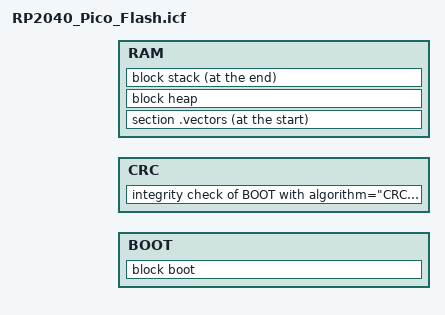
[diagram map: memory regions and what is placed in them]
/*********************************************************************
*                    SEGGER Microcontroller GmbH                     *
*                        The Embedded Experts                        *
**********************************************************************
*                                                                    *
*            (c) 2014 - 2021 SEGGER Microcontroller GmbH             *
*                                                                    *
*       www.segger.com     Support: support@segger.com               *
*                                                                    *
**********************************************************************
*                                                                    *
* All rights reserved.                                               *
*                                                                    *
* Redistribution and use in source and binary forms, with or         *
* without modification, are permitted provided that the following    *
* condition is met:                                                  *
*                                                                    *
* - Redistributions of source code must retain the above copyright   *
*   notice, this condition and the following disclaimer.             *
*                                                                    *
* THIS SOFTWARE IS PROVIDED BY THE COPYRIGHT HOLDERS AND             *
* CONTRIBUTORS "AS IS" AND ANY EXPRESS OR IMPLIED WARRANTIES,        *
* INCLUDING, BUT NOT LIMITED TO, THE IMPLIED WARRANTIES OF           *
* MERCHANTABILITY AND FITNESS FOR A PARTICULAR PURPOSE ARE           *
* DISCLAIMED. IN NO EVENT SHALL SEGGER Microcontroller BE LIABLE FOR *
* ANY DIRECT, INDIRECT, INCIDENTAL, SPECIAL, EXEMPLARY, OR           *
* CONSEQUENTIAL DAMAGES (INCLUDING, BUT NOT LIMITED TO, PROCUREMENT  *
* OF SUBSTITUTE GOODS OR SERVICES; LOSS OF USE, DATA, OR PROFITS;    *
* OR BUSINESS INTERRUPTION) HOWEVER CAUSED AND ON ANY THEORY OF      *
* LIABILITY, WHETHER IN CONTRACT, STRICT LIABILITY, OR TORT          *
* (INCLUDING NEGLIGENCE OR OTHERWISE) ARISING IN ANY WAY OUT OF THE  *
* USE OF THIS SOFTWARE, EVEN IF ADVISED OF THE POSSIBILITY OF SUCH   *
* DAMAGE.                                                            *
*                                                                    *
**********************************************************************
-------------------------- END-OF-HEADER -----------------------------

File    : RP2040_Pico_Flash.icf
Purpose : Linker script for RP2040 Pico board,
          for use with the SEGGER Linker.
Literature:
  [1]  SEGGER Linker User Guide (https://www.segger.com/doc/UM20005_Linker.html)
  [2]  SEGGER Linker Section Placement (https://wiki.segger.com/SEGGER_Linker_Script_Files)
*/

define memory with size = 4G;

//
// Combined regions per memory type
//
define region BOOT  = [from 0x20041F00 to 0x20041FFB];  // Copied  by ROM BTL of RP2040 to the end of the internal RAM
define region CRC   = [from 0x20041FFC to 0x20041FFF];  // Checked by ROM BTL of RP2040 to determine if 2nd stage BTL is valid and can be booted
define region FLASH = [from 0x10000000 to 0x10FFFFFF];
define region RAM   = [from 0x20000000 to 0x2003FFFF];
//
// Block definitions
//
define block boot                           { symbol _Stage2BTL };  // RP2040 2nd stage BTL section
define block ctors                          { section .ctors,     section .ctors.*, block with         alphabetical order { init_array } };
define block dtors                          { section .dtors,     section .dtors.*, block with reverse alphabetical order { fini_array } };
define block exidx                          { section .ARM.exidx, section .ARM.exidx.* };
define block tbss                           { section .tbss,      section .tbss.*  };
define block tdata                          { section .tdata,     section .tdata.* };
define block tls                            { block tbss, block tdata };
define block tdata_load                     { copy of block tdata };
define block heap  with size = __HEAPSIZE__,  alignment = 8, /* fill =0x00, */ readwrite access { };
define block stack with size = __STACKSIZE__, alignment = 8, /* fill =0xCD, */ readwrite access { };
//
// Explicit initialization settings for sections
// Packing options for initialize by copy: packing=auto/lzss/zpak/packbits
//
do not initialize                           { section .non_init, section .non_init.*, section .*.non_init, section .*.non_init.* };
do not initialize                           { section .no_init, section .no_init.*, section .*.no_init, section .*.no_init.* };   // Legacy sections, kept for backwards compatibility
do not initialize                           { section .noinit, section .noinit.*, section .*.noinit, section .*.noinit.* };       // Legacy sections, used by some SDKs/HALs
do not initialize                           { section .vectors_ram };
initialize by copy with packing=auto        { section .data, section .data.*, section .*.data, section .*.data.* };               // Static data sections
initialize by copy with packing=auto        { section .fast, section .fast.* };                                                   // "RAM Code" sections
initialize by symbol __SEGGER_init_heap     { block heap  };                                        // Init the heap if there is one
initialize by symbol __SEGGER_init_ctors    { block ctors };                                        // Call constructors for global objects which need to be constructed before reaching main (if any). Make sure this is done after setting up heap.
//
// FLASH Placement
//
// Special: Fill BOOT region (2nd stage BTL) with 0xFF to make sure that resulting hex file does not contain any gaps there.
// This is needed to actually force ES to perform 0xFF writes for this region when passing the download data to J-Link.
// Otherwise, it could happen that J-Link SW version V7.64c and earlier merge the gap with read data from the target.
// Merging with read data from the target is problematic if the 2nd stage BTL was bigger before and now is smaller,
// so that something that is a gap in the new BTL was != 0xFF in the old one.
// Here, reading back data from the target and merging it into the download data would mess up the CRC we calculated in the linker.
//
fill BOOT with 0xFF;
place in BOOT                               { block boot };                                         // RP2040 2nd stage BTL
place in CRC                                { integrity check of BOOT with algorithm="CRC-32/STM32" fill=0xFF }; // Placement of CRC
//
// RAM Placement
//
place at start of RAM                       { section .vectors };                                   // Vector table section
place in RAM with minimum size order        { block tdata_load,                                     // Thread-local-storage load image
                                              block exidx,                                          // ARM exception unwinding block
                                              block ctors,                                          // Constructors block
                                              block dtors,                                          // Destructors block
                                              readonly,                                             // Catch-all for readonly data (e.g. .rodata, .srodata)
                                              readexec                                              // Catch-all for (readonly) executable code (e.g. .text)
                                            };
                                             
place in RAM with auto order                { section .fast, section .fast.*,                       // "ramfunc" section
                                              block tls,                                            // Thread-local-storage block
                                              readwrite,                                            // Catch-all for initialized/uninitialized data sections (e.g. .data, .noinit)
                                              zeroinit                                              // Catch-all for zero-initialized data sections (e.g. .bss)
                                            };
place in RAM                                { block heap };                                         // Heap reserved block
place at end of RAM                         { block stack };                                        // Stack reserved block at the end
//
// Place <base> statements for regions at the end of the application, to make sure that linker placed everything before executing the <base> statements.
// <base> statements define the download address for the regions while the address in other staments is the execution address.
// This is needed because the RP2040's 2nd stage bootloader runs from internal SRAM later on but must be programmed into QSPI flash on download.
//
base region BOOT at 0x10000000;  // ES must downbload RP2040's 2nd stage BTL to start of flash. On boot, RP2040 copies the 2nd stage BTL to SRAM5 @ 0x20041000 and executes it from RAM.
base region CRC  at 0x100000FC;
